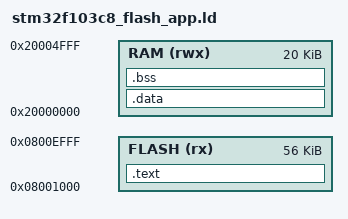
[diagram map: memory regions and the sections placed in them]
MEMORY
{
  FLASH (rx)  : ORIGIN = 0x08001000, LENGTH = 56K
  RAM (rwx)   : ORIGIN = 0x20000000, LENGTH = 20K
}

SECTIONS
{
  .text :
  {
    KEEP(*(.vectors))
    *(.text*)
    *(.rodata*)
    . = ALIGN(4);
    _etext = .;
  } > FLASH

  .data : AT (_etext)
  {
    _sdata = .;
    *(.data*)
    . = ALIGN(4);
    _edata = .;
  } > RAM

  .bss :
  {
    _sbss = .;
    *(.bss*)
    *(COMMON)
    . = ALIGN(4);
    _ebss = .;
  } > RAM

  /DISCARD/ :
  {
    libc.a ( * )
    libm.a ( * )
    libgcc.a ( * )
  }
}
